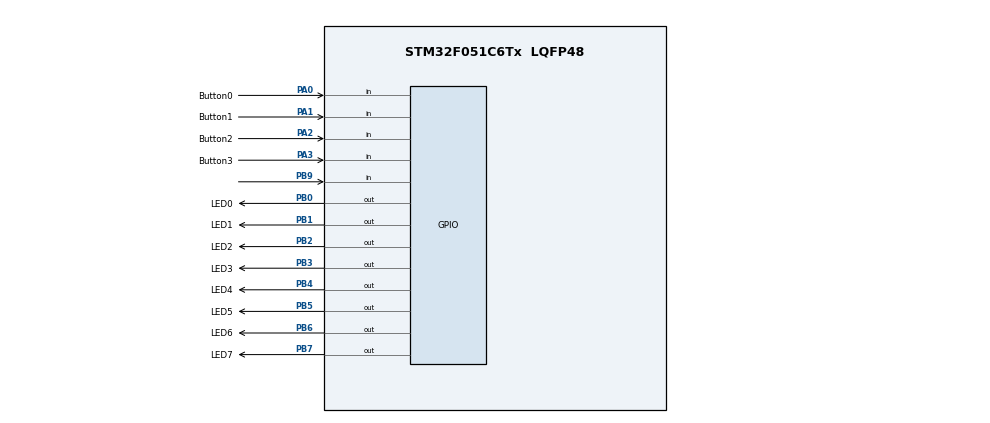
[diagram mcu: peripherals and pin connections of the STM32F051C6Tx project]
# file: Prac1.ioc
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Mcu.Family=STM32F0
Mcu.Name=STM32F051C6Tx
Mcu.Package=LQFP48
PA0.GPIO_Label=Button0
PA0.GPIO_PuPd=GPIO_PULLUP
PA0.Signal=GPIO_Input
PA1.GPIO_Label=Button1
PA1.GPIO_PuPd=GPIO_PULLUP
PA1.Signal=GPIO_Input
PA13.Mode=Serial_Wire
PA13.Signal=SYS_SWDIO
PA14.Mode=Serial_Wire
PA14.Signal=SYS_SWCLK
PA2.GPIO_Label=Button2
PA2.GPIO_PuPd=GPIO_PULLUP
PA2.Signal=GPIO_Input
PA3.GPIO_Label=Button3
PA3.GPIO_PuPd=GPIO_PULLUP
PA3.Signal=GPIO_Input
PB0.GPIO_Label=LED0
PB0.Signal=GPIO_Output
PB1.GPIO_Label=LED1
PB1.Signal=GPIO_Output
PB2.GPIO_Label=LED2
PB2.Signal=GPIO_Output
PB3.GPIO_Label=LED3
PB3.Signal=GPIO_Output
PB4.GPIO_Label=LED4
PB4.Signal=GPIO_Output
PB5.GPIO_Label=LED5
PB5.Signal=GPIO_Output
PB6.GPIO_Label=LED6
PB6.Signal=GPIO_Output
PB7.GPIO_Label=LED7
PB7.Signal=GPIO_Output
PB9.Signal=GPIO_Input
PF0-OSC_IN.Mode=HSE-External-Oscillator
PF0-OSC_IN.Signal=RCC_OSC_IN
PF1-OSC_OUT.Mode=HSE-External-Oscillator
PF1-OSC_OUT.Signal=RCC_OSC_OUT
ProjectManager.HeapSize=0x200
ProjectManager.StackSize=0x400
ProjectManager.TargetToolchain=STM32CubeIDE
TIM16.AutoReloadPreload=TIM_AUTORELOAD_PRELOAD_ENABLE
TIM16.Period=1000-1
TIM16.Prescaler=8000-1
VP_TIM16_VS_ClockSourceINT.Mode=Enable_Timer
board=custom

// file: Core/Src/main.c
/* USER CODE BEGIN Header */
/**
  ******************************************************************************
  * @file           : main.c
  * @brief          : Main program body
  ******************************************************************************
  * @attention
  *
  * Copyright (c) 2023 STMicroelectronics.
  * All rights reserved.
  *
  * This software is licensed under terms that can be found in the LICENSE file
  * in the root directory of this software component.
  * If no LICENSE file comes with this software, it is provided AS-IS.
  *
  ******************************************************************************
  */
/* USER CODE END Header */
#include "main.h"

/* USER CODE BEGIN Includes */
#include <stdint.h>
#include "stm32f0xx.h"
/* USER CODE END Includes */

TIM_HandleTypeDef htim16;

/* USER CODE BEGIN PV */
// TODO: Define input variables

}; //9x8 2D Array to represent 9 patters of 8 LEDs

/* USER CODE END PV */

void SystemClock_Config(void);
static void MX_GPIO_Init(void);
static void MX_TIM16_Init(void);
/* USER CODE BEGIN PFP */
void TIM16_IRQHandler(void);
/* USER CODE END PFP */

int main(void)
{

  /* MCU Configuration--------------------------------------------------------*/

  /* Reset of all peripherals, Initializes the Flash interface and the Systick. */
  HAL_Init();

  /* Configure the system clock */
  SystemClock_Config();

  /* Initialize all configured peripherals */
  MX_GPIO_Init();
  MX_TIM16_Init();
  /* USER CODE BEGIN 2 */

  HAL_TIM_Base_Start_IT(&htim16);
  /* USER CODE END 2 */

  /* Infinite loop */
  while (1)
  {

    /* USER CODE BEGIN 3 */

    // TODO: Check pushbuttons to change timer delay

  }
  /* USER CODE END 3 */
}

void SystemClock_Config(void)
{
  LL_FLASH_SetLatency(LL_FLASH_LATENCY_0);
  while(LL_FLASH_GetLatency() != LL_FLASH_LATENCY_0)
  {
  }
  LL_RCC_HSI_Enable();

   /* Wait till HSI is ready */
  while(LL_RCC_HSI_IsReady() != 1)
  {

  }
  LL_RCC_HSI_SetCalibTrimming(16);
  LL_RCC_SetAHBPrescaler(LL_RCC_SYSCLK_DIV_1);
  LL_RCC_SetAPB1Prescaler(LL_RCC_APB1_DIV_1);
  LL_RCC_SetSysClkSource(LL_RCC_SYS_CLKSOURCE_HSI);

   /* Wait till System clock is ready */
  while(LL_RCC_GetSysClkSource() != LL_RCC_SYS_CLKSOURCE_STATUS_HSI)
  {

  }
  LL_SetSystemCoreClock(8000000);

   /* Update the time base */
  if (HAL_InitTick (TICK_INT_PRIORITY) != HAL_OK)
  {
    Error_Handler();
  }
}

static void MX_TIM16_Init(void)
{

  htim16.Instance = TIM16;
  htim16.Init.Prescaler = 8000-1;
  htim16.Init.CounterMode = TIM_COUNTERMODE_UP;
  htim16.Init.Period = 1000-1;
  htim16.Init.ClockDivision = TIM_CLOCKDIVISION_DIV1;
  htim16.Init.RepetitionCounter = 0;
  htim16.Init.AutoReloadPreload = TIM_AUTORELOAD_PRELOAD_ENABLE;
  if (HAL_TIM_Base_Init(&htim16) != HAL_OK)
  {
    Error_Handler();
  }
  /* USER CODE BEGIN TIM16_Init 2 */
  NVIC_EnableIRQ(TIM16_IRQn);
  /* USER CODE END TIM16_Init 2 */

}

static void MX_GPIO_Init(void)
{
  LL_GPIO_InitTypeDef GPIO_InitStruct = {0};

  /* GPIO Ports Clock Enable */
  LL_AHB1_GRP1_EnableClock(LL_AHB1_GRP1_PERIPH_GPIOF);
  LL_AHB1_GRP1_EnableClock(LL_AHB1_GRP1_PERIPH_GPIOA);
  LL_AHB1_GRP1_EnableClock(LL_AHB1_GRP1_PERIPH_GPIOB);

  /**/
  LL_GPIO_ResetOutputPin(LED0_GPIO_Port, LED0_Pin);

  /**/
  LL_GPIO_ResetOutputPin(LED1_GPIO_Port, LED1_Pin);

  /**/
  LL_GPIO_ResetOutputPin(LED2_GPIO_Port, LED2_Pin);

  /**/
  LL_GPIO_ResetOutputPin(LED3_GPIO_Port, LED3_Pin);

  /**/
  LL_GPIO_ResetOutputPin(LED4_GPIO_Port, LED4_Pin);

  /**/
  LL_GPIO_ResetOutputPin(LED5_GPIO_Port, LED5_Pin);

  /**/
  LL_GPIO_ResetOutputPin(LED6_GPIO_Port, LED6_Pin);

  /**/
  LL_GPIO_ResetOutputPin(LED7_GPIO_Port, LED7_Pin);

  /**/
  GPIO_InitStruct.Pin = Button0_Pin;
  GPIO_InitStruct.Mode = LL_GPIO_MODE_INPUT;
  GPIO_InitStruct.Pull = LL_GPIO_PULL_UP;
  LL_GPIO_Init(Button0_GPIO_Port, &GPIO_InitStruct);

  /**/
  GPIO_InitStruct.Pin = Button1_Pin;
  GPIO_InitStruct.Mode = LL_GPIO_MODE_INPUT;
  GPIO_InitStruct.Pull = LL_GPIO_PULL_UP;
  LL_GPIO_Init(Button1_GPIO_Port, &GPIO_InitStruct);

  /**/
  GPIO_InitStruct.Pin = Button2_Pin;
  GPIO_InitStruct.Mode = LL_GPIO_MODE_INPUT;
  GPIO_InitStruct.Pull = LL_GPIO_PULL_UP;
  LL_GPIO_Init(Button2_GPIO_Port, &GPIO_InitStruct);

  /**/
  GPIO_InitStruct.Pin = Button3_Pin;
  GPIO_InitStruct.Mode = LL_GPIO_MODE_INPUT;
  GPIO_InitStruct.Pull = LL_GPIO_PULL_UP;
  LL_GPIO_Init(Button3_GPIO_Port, &GPIO_InitStruct);

  /**/
  GPIO_InitStruct.Pin = LED0_Pin;
  GPIO_InitStruct.Mode = LL_GPIO_MODE_OUTPUT;
  GPIO_InitStruct.Speed = LL_GPIO_SPEED_FREQ_LOW;
  GPIO_InitStruct.OutputType = LL_GPIO_OUTPUT_PUSHPULL;
  GPIO_InitStruct.Pull = LL_GPIO_PULL_NO;
  LL_GPIO_Init(LED0_GPIO_Port, &GPIO_InitStruct);

  /**/
  GPIO_InitStruct.Pin = LED1_Pin;
  GPIO_InitStruct.Mode = LL_GPIO_MODE_OUTPUT;
  GPIO_InitStruct.Speed = LL_GPIO_SPEED_FREQ_LOW;
  GPIO_InitStruct.OutputType = LL_GPIO_OUTPUT_PUSHPULL;
  GPIO_InitStruct.Pull = LL_GPIO_PULL_NO;
  LL_GPIO_Init(LED1_GPIO_Port, &GPIO_InitStruct);

  /**/
  GPIO_InitStruct.Pin = LED2_Pin;
  GPIO_InitStruct.Mode = LL_GPIO_MODE_OUTPUT;
  GPIO_InitStruct.Speed = LL_GPIO_SPEED_FREQ_LOW;
  GPIO_InitStruct.OutputType = LL_GPIO_OUTPUT_PUSHPULL;
  GPIO_InitStruct.Pull = LL_GPIO_PULL_NO;
  LL_GPIO_Init(LED2_GPIO_Port, &GPIO_InitStruct);

  /**/
  GPIO_InitStruct.Pin = LED3_Pin;
  GPIO_InitStruct.Mode = LL_GPIO_MODE_OUTPUT;
  GPIO_InitStruct.Speed = LL_GPIO_SPEED_FREQ_LOW;
  GPIO_InitStruct.OutputType = LL_GPIO_OUTPUT_PUSHPULL;
  GPIO_InitStruct.Pull = LL_GPIO_PULL_NO;
  LL_GPIO_Init(LED3_GPIO_Port, &GPIO_InitStruct);

  /**/
  GPIO_InitStruct.Pin = LED4_Pin;
  GPIO_InitStruct.Mode = LL_GPIO_MODE_OUTPUT;
  GPIO_InitStruct.Speed = LL_GPIO_SPEED_FREQ_LOW;
  GPIO_InitStruct.OutputType = LL_GPIO_OUTPUT_PUSHPULL;
  GPIO_InitStruct.Pull = LL_GPIO_PULL_NO;
  LL_GPIO_Init(LED4_GPIO_Port, &GPIO_InitStruct);

  /**/
  GPIO_InitStruct.Pin = LED5_Pin;
  GPIO_InitStruct.Mode = LL_GPIO_MODE_OUTPUT;
  GPIO_InitStruct.Speed = LL_GPIO_SPEED_FREQ_LOW;
  GPIO_InitStruct.OutputType = LL_GPIO_OUTPUT_PUSHPULL;
  GPIO_InitStruct.Pull = LL_GPIO_PULL_NO;
  LL_GPIO_Init(LED5_GPIO_Port, &GPIO_InitStruct);

  /**/
  GPIO_InitStruct.Pin = LED6_Pin;
  GPIO_InitStruct.Mode = LL_GPIO_MODE_OUTPUT;
  GPIO_InitStruct.Speed = LL_GPIO_SPEED_FREQ_LOW;
  GPIO_InitStruct.OutputType = LL_GPIO_OUTPUT_PUSHPULL;
  GPIO_InitStruct.Pull = LL_GPIO_PULL_NO;
  LL_GPIO_Init(LED6_GPIO_Port, &GPIO_InitStruct);

  /**/
  GPIO_InitStruct.Pin = LED7_Pin;
  GPIO_InitStruct.Mode = LL_GPIO_MODE_OUTPUT;
  GPIO_InitStruct.Speed = LL_GPIO_SPEED_FREQ_LOW;
  GPIO_InitStruct.OutputType = LL_GPIO_OUTPUT_PUSHPULL;
  GPIO_InitStruct.Pull = LL_GPIO_PULL_NO;
  LL_GPIO_Init(LED7_GPIO_Port, &GPIO_InitStruct);

  /**/
  GPIO_InitStruct.Pin = LL_GPIO_PIN_9;
  GPIO_InitStruct.Mode = LL_GPIO_MODE_INPUT;
  GPIO_InitStruct.Pull = LL_GPIO_PULL_NO;
  LL_GPIO_Init(GPIOB, &GPIO_InitStruct);

}

/* USER CODE BEGIN 4 */

void TIM16_IRQHandler(void)
{
	// Acknowledge interrupt
	HAL_TIM_IRQHandler(&htim16);
}
/* USER CODE END 4 */

void Error_Handler(void)
{
  __disable_irq();
  while (1)
  {
  }
}
